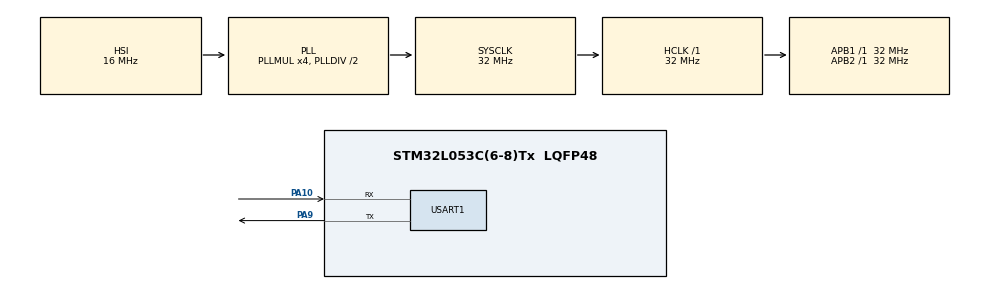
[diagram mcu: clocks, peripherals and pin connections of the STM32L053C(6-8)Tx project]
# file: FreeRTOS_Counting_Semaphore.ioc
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FREERTOS.Tasks01=defaultTask,0,128,StartDefaultTask,Default,NULL,Dynamic,NULL,NULL
FREERTOS.configUSE_COUNTING_SEMAPHORES=1
Mcu.Family=STM32L0
Mcu.Name=STM32L053C(6-8)Tx
Mcu.Package=LQFP48
NVIC.TIM6_DAC_IRQn=true\:3\:0\:false\:false\:true\:false\:false\:true\:true
NVIC.TimeBase=TIM6_DAC_IRQn
NVIC.TimeBaseIP=TIM6
NVIC.USART1_IRQn=true\:3\:0\:false\:false\:true\:true\:true\:true\:true
PA10.Mode=Asynchronous
PA10.Signal=USART1_RX
PA13.Mode=Serial_Wire
PA13.Signal=SYS_SWDIO
PA14.Mode=Serial_Wire
PA14.Signal=SYS_SWCLK
PA9.Mode=Asynchronous
PA9.Signal=USART1_TX
ProjectManager.HeapSize=0x200
ProjectManager.StackSize=0x400
ProjectManager.TargetToolchain=STM32CubeIDE
RCC.AHBFreq_Value=32000000
RCC.APB1Freq_Value=32000000
RCC.APB1TimFreq_Value=32000000
RCC.APB2Freq_Value=32000000
RCC.APB2TimFreq_Value=32000000
RCC.HCLKFreq_Value=32000000
RCC.HSE_VALUE=8000000
RCC.HSI16_VALUE=16000000
RCC.HSI48MClockSelection=RCC_USBCLKSOURCE_HSI48
RCC.HSI48_VALUE=48000000
RCC.HSI_VALUE=16000000
RCC.LSE_VALUE=32768
RCC.MSI_VALUE=2097000
RCC.PLLMUL=RCC_PLLMUL_4
RCC.RTCClockSelectionVirtual=RCC_RTCCLKSOURCE_LSE
RCC.SYSCLKFreq_VALUE=32000000
RCC.SYSCLKSource=RCC_SYSCLKSOURCE_PLLCLK
RCC.VCOOutputFreq_Value=64000000
USART1.VirtualMode-Asynchronous=VM_ASYNC
VP_FREERTOS_VS_CMSIS_V1.Mode=CMSIS_V1
VP_SYS_VS_tim6.Mode=TIM6
board=STM32L0538-DISCO

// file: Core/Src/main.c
/* USER CODE BEGIN Header */
/**
 ******************************************************************************
 * @file           : main.c
 * @brief          : Main program body
 ******************************************************************************
 * @attention
 *
 * Copyright (c) 2023 STMicroelectronics.
 * All rights reserved.
 *
 * This software is licensed under terms that can be found in the LICENSE file
 * in the root directory of this software component.
 * If no LICENSE file comes with this software, it is provided AS-IS.
 *
 ******************************************************************************
 */
/* USER CODE END Header */
#include "main.h"
//#include "cmsis_os.h"

/* USER CODE BEGIN Includes */

#include "FreeRTOS.h"
#include "task.h"
#include "timers.h"
#include "queue.h"
#include "semphr.h"
#include "event_groups.h"

#include "stdlib.h"
#include "string.h"

/* USER CODE END Includes */

UART_HandleTypeDef huart1;

void SystemClock_Config(void);
static void MX_GPIO_Init(void);
static void MX_USART1_UART_Init(void);

/* USER CODE BEGIN 0 */

//create task defines
TaskHandle_t HPThandler;
void HPT_TASK(void *pvParameters);

TaskHandle_t LPThandler;
void LPT_TASK(void *pvParameters);

//Semaphore related
SemaphoreHandle_t CountingSem;

//Resource related
int resourse[3] = { 111, 222, 333 };
int indx = 0;

//UART related
uint8_t rx_data = 0;

/* USER CODE END 0 */

int main(void) {

	/* MCU Configuration--------------------------------------------------------*/

	/* Reset of all peripherals, Initializes the Flash interface and the Systick. */
	HAL_Init();

	/* Configure the system clock */
	SystemClock_Config();

	/* Initialize all configured peripherals */
	MX_GPIO_Init();
	MX_USART1_UART_Init();
	/* USER CODE BEGIN 2 */

	HAL_UART_Receive_IT(&huart1, &rx_data, 1);
	HAL_Delay(1000);

	CountingSem = xSemaphoreCreateCounting(3, 0);
	if (CountingSem == NULL)
		HAL_UART_Transmit(&huart1,
				(uint8_t*) "Unable to Create Semaphore...\r\n", 35, 1000);
	else
		HAL_UART_Transmit(&huart1,
				(uint8_t*) "Counting Semaphore created successfully...\r\n", 50,
				1000);

	//create task
	xTaskCreate(HPT_TASK, "HPT", 128, NULL, 2, &HPThandler);
	xTaskCreate(LPT_TASK, "LPT", 128, NULL, 1, &LPThandler);

	vTaskStartScheduler();

	/* USER CODE END 2 */

	/* We should never get here as control is now taken by the scheduler */
	/* Infinite loop */
	while (1) {

	}
}

void SystemClock_Config(void) {
	RCC_OscInitTypeDef RCC_OscInitStruct = { 0 };
	RCC_ClkInitTypeDef RCC_ClkInitStruct = { 0 };
	RCC_PeriphCLKInitTypeDef PeriphClkInit = { 0 };

	/** Configure the main internal regulator output voltage
	 */
	__HAL_PWR_VOLTAGESCALING_CONFIG(PWR_REGULATOR_VOLTAGE_SCALE1);

	/** Initializes the RCC Oscillators according to the specified parameters
	 * in the RCC_OscInitTypeDef structure.
	 */
	RCC_OscInitStruct.OscillatorType = RCC_OSCILLATORTYPE_HSI;
	RCC_OscInitStruct.HSIState = RCC_HSI_ON;
	RCC_OscInitStruct.HSICalibrationValue = RCC_HSICALIBRATION_DEFAULT;
	RCC_OscInitStruct.PLL.PLLState = RCC_PLL_ON;
	RCC_OscInitStruct.PLL.PLLSource = RCC_PLLSOURCE_HSI;
	RCC_OscInitStruct.PLL.PLLMUL = RCC_PLLMUL_4;
	RCC_OscInitStruct.PLL.PLLDIV = RCC_PLLDIV_2;
	if (HAL_RCC_OscConfig(&RCC_OscInitStruct) != HAL_OK) {
		Error_Handler();
	}

	/** Initializes the CPU, AHB and APB buses clocks
	 */
	RCC_ClkInitStruct.ClockType = RCC_CLOCKTYPE_HCLK | RCC_CLOCKTYPE_SYSCLK
			| RCC_CLOCKTYPE_PCLK1 | RCC_CLOCKTYPE_PCLK2;
	RCC_ClkInitStruct.SYSCLKSource = RCC_SYSCLKSOURCE_PLLCLK;
	RCC_ClkInitStruct.AHBCLKDivider = RCC_SYSCLK_DIV1;
	RCC_ClkInitStruct.APB1CLKDivider = RCC_HCLK_DIV1;
	RCC_ClkInitStruct.APB2CLKDivider = RCC_HCLK_DIV1;

	if (HAL_RCC_ClockConfig(&RCC_ClkInitStruct, FLASH_LATENCY_1) != HAL_OK) {
		Error_Handler();
	}
	PeriphClkInit.PeriphClockSelection = RCC_PERIPHCLK_USART1;
	PeriphClkInit.Usart1ClockSelection = RCC_USART1CLKSOURCE_PCLK2;
	if (HAL_RCCEx_PeriphCLKConfig(&PeriphClkInit) != HAL_OK) {
		Error_Handler();
	}
}

static void MX_USART1_UART_Init(void) {

	huart1.Instance = USART1;
	huart1.Init.BaudRate = 115200;
	huart1.Init.WordLength = UART_WORDLENGTH_8B;
	huart1.Init.StopBits = UART_STOPBITS_1;
	huart1.Init.Parity = UART_PARITY_NONE;
	huart1.Init.Mode = UART_MODE_TX_RX;
	huart1.Init.HwFlowCtl = UART_HWCONTROL_NONE;
	huart1.Init.OverSampling = UART_OVERSAMPLING_16;
	huart1.Init.OneBitSampling = UART_ONE_BIT_SAMPLE_DISABLE;
	huart1.AdvancedInit.AdvFeatureInit = UART_ADVFEATURE_NO_INIT;
	if (HAL_UART_Init(&huart1) != HAL_OK) {
		Error_Handler();
	}

}

static void MX_GPIO_Init(void) {

	/* GPIO Ports Clock Enable */
	__HAL_RCC_GPIOA_CLK_ENABLE();

}

/* USER CODE BEGIN 4 */

void HPT_TASK (void *pvParameters)
{
	char sresource[3];
	int semcount = 0;
	char ssemcount[2];

	// Give 3 semaphores at the beginning..
	xSemaphoreGive(CountingSem);
	xSemaphoreGive(CountingSem);
	xSemaphoreGive(CountingSem);

	while (1)
	{
		char str[150];
		strcpy(str, "Entered HPT Task\r\nAbout to ACQUIRE the Semaphore\r\n");
		semcount = uxSemaphoreGetCount(CountingSem);
		itoa (semcount, ssemcount, 10);
		strcat (str, "Tokens available are: ");
		strcat (str, ssemcount);
		strcat (str, "\r\n\r\n");
		HAL_UART_Transmit(&huart1, (uint8_t *)str, strlen (str), HAL_MAX_DELAY);

		xSemaphoreTake(CountingSem, portMAX_DELAY);

		itoa (resourse[indx], sresource, 10);
		strcpy (str, "Leaving HPT Task\r\nData ACCESSED is:: ");
		strcat (str, sresource);
		strcat (str, "\r\nNot releasing the Semaphore\r\n\r\n\r\n");
		HAL_UART_Transmit(&huart1, (uint8_t *)str, strlen (str), HAL_MAX_DELAY);

		indx++;
		if (indx>2) indx=0;

		vTaskDelay(3000);
//		vTaskDelete(NULL);
	}
}
void LPT_TASK(void *pvParameters) {

	char sresource[3];

	while (1) {
		char str[150];
		strcpy(str, "Entered LPT Task\r\nAbout to acquire semaphore\r\n");
		HAL_UART_Transmit(&huart1, (uint8_t*) str, strlen(str), HAL_MAX_DELAY);

		xSemaphoreTake(CountingSem, portMAX_DELAY);

		itoa(resourse[indx], sresource, 10);
		strcpy(str, "Leaving LPT Task\r\nData accessed is ::");
		strcat(str, sresource);
		strcat(str, "\r\nNot releasing the semaphore\r\n\r\n\r\n\r\n");
		HAL_UART_Transmit(&huart1, (uint8_t*) str, strlen(str), HAL_MAX_DELAY);

		indx++;
		if (indx > 2)
			indx = 0;

		vTaskDelay(3000);
		}
}

//UART callBack function
void HAL_UART_RxCpltCallback(UART_HandleTypeDef *huart)
{
	HAL_UART_Receive_IT(huart, &rx_data, 1);
	if (rx_data == 'r')
	{
		// release the semaphore here
		 /* The xHigherPriorityTaskWoken parameter must be initialized to pdFALSE as
		 it will get set to pdTRUE inside the interrupt safe API function if a
		 context switch is required. */
		BaseType_t xHigherPriorityTaskWoken = pdFALSE;

		xSemaphoreGiveFromISR(CountingSem, &xHigherPriorityTaskWoken);  // ISR SAFE VERSION
		xSemaphoreGiveFromISR(CountingSem, &xHigherPriorityTaskWoken);  // ISR SAFE VERSION
		xSemaphoreGiveFromISR(CountingSem, &xHigherPriorityTaskWoken);  // ISR SAFE VERSION

		/* Pass the xHigherPriorityTaskWoken value into portEND_SWITCHING_ISR(). If
		 xHigherPriorityTaskWoken was set to pdTRUE inside xSemaphoreGiveFromISR()
		 then calling portEND_SWITCHING_ISR() will request a context switch. If
		 xHigherPriorityTaskWoken is still pdFALSE then calling
		 portEND_SWITCHING_ISR() will have no effect */

		portEND_SWITCHING_ISR( xHigherPriorityTaskWoken );
	}
}

/* USER CODE END 4 */

void HAL_TIM_PeriodElapsedCallback(TIM_HandleTypeDef *htim) {
	if (htim->Instance == TIM6) {
		HAL_IncTick();
	}
}

void Error_Handler(void) {
	__disable_irq();
	while (1) {
	}
}
